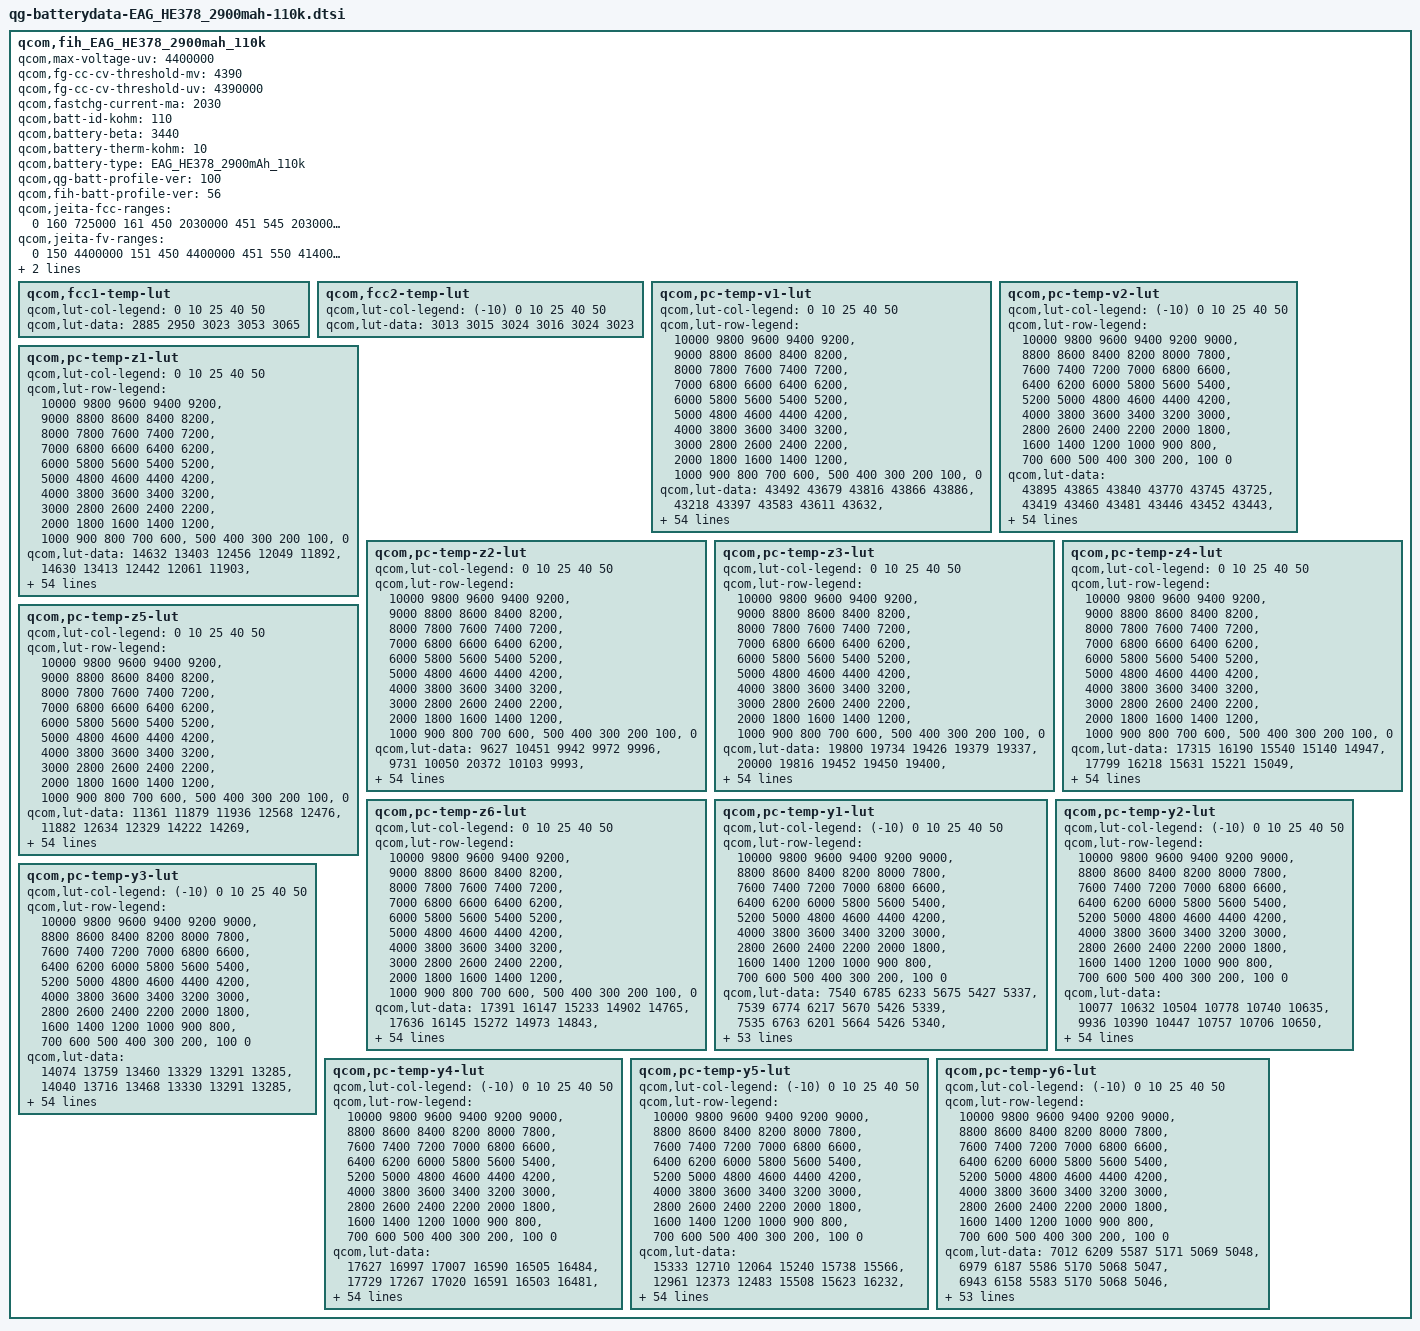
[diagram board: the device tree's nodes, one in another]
qcom,fih_EAG_HE378_2900mah_110k {
	/* 3637030_FIH_Eagles_Scud_3000mAH_averaged_MasterSlave_Nov23rd2018 */
	qcom,max-voltage-uv = <4400000>;
	qcom,fg-cc-cv-threshold-mv = <4390>;
	qcom,fg-cc-cv-threshold-uv = <4390000>;
	qcom,fastchg-current-ma = <2030>;
	qcom,batt-id-kohm = <110>;
	qcom,battery-beta = <3440>;
	qcom,battery-therm-kohm = <10>;
	qcom,battery-type =
		"EAG_HE378_2900mAh_110k";
	qcom,qg-batt-profile-ver = <100>;
	qcom,fih-batt-profile-ver = <56>;

	qcom,jeita-fcc-ranges = <0   160   725000
				 161 450  2030000
				 451 545  2030000
				 546 550  100000>;
	qcom,jeita-fv-ranges =  <0   150  4400000
				 151 450  4400000
				 451 550  4140000>;

	qcom,jeita-soft-thresholds = <0x257d 0xfb3>; 
	qcom,jeita-hard-thresholds = <0x3733 0xc19>;

	qcom,fcc1-temp-lut {
		qcom,lut-col-legend = <0 10 25 40 50>;
		qcom,lut-data = <2885 2950 3023 3053 3065>;
	};

	qcom,fcc2-temp-lut {
		qcom,lut-col-legend = <(-10) 0 10 25 40 50>;
		qcom,lut-data = <3013 3015 3024 3016 3024 3023>;
	};

	qcom,pc-temp-v1-lut {
		qcom,lut-col-legend = <0 10 25 40 50>;
		qcom,lut-row-legend = <10000 9800 9600 9400 9200>,
			<9000 8800 8600 8400 8200>,
			<8000 7800 7600 7400 7200>,
			<7000 6800 6600 6400 6200>,
			<6000 5800 5600 5400 5200>,
			<5000 4800 4600 4400 4200>,
			<4000 3800 3600 3400 3200>,
			<3000 2800 2600 2400 2200>,
			<2000 1800 1600 1400 1200>,
			<1000 900 800 700 600>,
			<500 400 300 200 100>,
			<0>;
		qcom,lut-data = <43492 43679 43816 43866 43886>,
			<43218 43397 43583 43611 43632>,
			<42964 43134 43319 43364 43390>,
			<42722 42890 43058 43122 43150>,
			<42491 42657 42813 42881 42911>,
			<42269 42424 42574 42642 42673>,
			<42052 42194 42339 42406 42437>,
			<41839 41973 42105 42173 42203>,
			<41632 41756 41877 41943 41972>,
			<41435 41546 41653 41714 41744>,
			<41253 41350 41436 41487 41520>,
			<41062 41167 41230 41268 41300>,
			<40845 40972 41036 41058 41081>,
			<40609 40743 40833 40852 40868>,
			<40379 40503 40607 40639 40662>,
			<40143 40281 40382 40427 40462>,
			<39940 40071 40185 40237 40271>,
			<39798 39897 40004 40066 40091>,
			<39687 39773 39844 39903 39918>,
			<39577 39666 39712 39749 39757>,
			<39464 39538 39577 39597 39602>,
			<39352 39390 39393 39405 39419>,
			<39231 39227 39170 39150 39182>,
			<39101 39027 38968 38929 38963>,
			<38973 38812 38770 38782 38808>,
			<38847 38661 38612 38664 38680>,
			<38726 38553 38532 38563 38569>,
			<38623 38472 38478 38476 38470>,
			<38532 38413 38423 38394 38379>,
			<38455 38369 38364 38310 38294>,
			<38394 38327 38306 38233 38216>,
			<38343 38287 38249 38168 38147>,
			<38300 38250 38194 38112 38087>,
			<38266 38216 38144 38061 38030>,
			<38237 38186 38102 38018 37980>,
			<38208 38155 38061 37975 37931>,
			<38182 38127 38022 37927 37875>,
			<38148 38093 37981 37874 37813>,
			<38099 38038 37924 37809 37740>,
			<38032 37950 37835 37723 37653>,
			<37943 37850 37730 37622 37553>,
			<37813 37734 37616 37509 37439>,
			<37682 37599 37485 37377 37308>,
			<37559 37434 37325 37221 37149>,
			<37402 37288 37175 37076 37008>,
			<37285 37182 37082 36986 36921>,
			<37246 37153 37056 36961 36900>,
			<37212 37135 37039 36948 36884>,
			<37183 37110 37019 36930 36866>,
			<37136 37080 36978 36883 36812>,
			<36954 36869 36762 36646 36556>,
			<36515 36443 36336 36217 36123>,
			<35944 35875 35768 35647 35554>,
			<35174 35101 34994 34868 34773>,
			<33948 33886 33789 33665 33569>,
			<30000 30000 30000 30000 30000>;
	};

	qcom,pc-temp-v2-lut {
		qcom,lut-col-legend = <(-10) 0 10 25 40 50>;
		qcom,lut-row-legend = <10000 9800 9600 9400 9200 9000>,
			<8800 8600 8400 8200 8000 7800>,
			<7600 7400 7200 7000 6800 6600>,
			<6400 6200 6000 5800 5600 5400>,
			<5200 5000 4800 4600 4400 4200>,
			<4000 3800 3600 3400 3200 3000>,
			<2800 2600 2400 2200 2000 1800>,
			<1600 1400 1200 1000 900 800>,
			<700 600 500 400 300 200>,
			<100 0>;
		qcom,lut-data = <43895 43865 43840 43770 43745 43725>,
			<43419 43460 43481 43446 43452 43443>,
			<43012 43092 43152 43146 43176 43176>,
			<42694 42764 42857 42874 42917 42922>,
			<42440 42467 42591 42628 42676 42681>,
			<42204 42212 42337 42390 42440 42446>,
			<41967 42011 42090 42156 42206 42212>,
			<41738 41827 41851 41926 41975 41981>,
			<41515 41588 41616 41701 41748 41754>,
			<41283 41284 41380 41479 41524 41529>,
			<41102 41073 41170 41265 41304 41309>,
			<40998 40996 41004 41067 41090 41092>,
			<40896 40932 40841 40872 40880 40880>,
			<40632 40730 40623 40661 40675 40675>,
			<40029 40240 40341 40434 40473 40473>,
			<39581 39847 40086 40222 40278 40281>,
			<39408 39663 39881 40029 40091 40096>,
			<39281 39517 39694 39851 39911 39919>,
			<39135 39345 39514 39699 39745 39751>,
			<38985 39157 39342 39571 39593 39593>,
			<38822 38977 39166 39417 39422 39419>,
			<38616 38815 38974 39183 39204 39204>,
			<38421 38658 38790 38932 38982 38987>,
			<38316 38479 38635 38747 38798 38806>,
			<38248 38280 38499 38596 38635 38645>,
			<38189 38154 38368 38468 38499 38508>,
			<38132 38096 38229 38358 38389 38397>,
			<38079 38053 38106 38260 38292 38298>,
			<38026 38009 38020 38171 38203 38207>,
			<37976 37968 37950 38090 38121 38124>,
			<37925 37929 37900 38016 38048 38049>,
			<37874 37892 37867 37945 37982 37980>,
			<37822 37854 37837 37881 37920 37916>,
			<37769 37816 37806 37828 37856 37854>,
			<37718 37776 37776 37783 37791 37794>,
			<37664 37734 37739 37737 37720 37717>,
			<37605 37690 37696 37687 37639 37608>,
			<37545 37641 37646 37633 37556 37494>,
			<37483 37582 37587 37568 37477 37407>,
			<37419 37513 37520 37493 37398 37329>,
			<37354 37431 37440 37408 37314 37245>,
			<37288 37327 37337 37310 37224 37156>,
			<37217 37213 37214 37194 37116 37047>,
			<37141 37091 37067 37054 36978 36910>,
			<37057 36990 36939 36909 36844 36789>,
			<36951 36908 36852 36850 36802 36754>,
			<36891 36872 36826 36834 36789 36742>,
			<36821 36835 36796 36816 36774 36728>,
			<36731 36793 36760 36788 36747 36700>,
			<36587 36707 36680 36721 36671 36604>,
			<36333 36481 36454 36500 36391 36297>,
			<35934 36047 36015 36047 35917 35811>,
			<35345 35425 35394 35439 35295 35169>,
			<34458 34541 34532 34625 34448 34306>,
			<33189 33247 33193 33394 33197 33040>,
			<28891 28389 28310 28452 28627 28586>;
	};

	qcom,pc-temp-z1-lut {
		qcom,lut-col-legend = <0 10 25 40 50>;
		qcom,lut-row-legend = <10000 9800 9600 9400 9200>,
			<9000 8800 8600 8400 8200>,
			<8000 7800 7600 7400 7200>,
			<7000 6800 6600 6400 6200>,
			<6000 5800 5600 5400 5200>,
			<5000 4800 4600 4400 4200>,
			<4000 3800 3600 3400 3200>,
			<3000 2800 2600 2400 2200>,
			<2000 1800 1600 1400 1200>,
			<1000 900 800 700 600>,
			<500 400 300 200 100>,
			<0>;
		qcom,lut-data = <14632 13403 12456 12049 11892>,
			<14630 13413 12442 12061 11903>,
			<14615 13407 12449 12050 11897>,
			<14599 13392 12450 12040 11893>,
			<14585 13378 12440 12029 11888>,
			<14567 13368 12427 12018 11882>,
			<14556 13361 12416 12010 11877>,
			<14566 13354 12406 12007 11874>,
			<14577 13340 12400 12004 11872>,
			<14565 13326 12395 12000 11869>,
			<14533 13324 12391 11997 11866>,
			<14495 13327 12394 11996 11864>,
			<14446 13328 12405 11996 11863>,
			<14388 13296 12409 11997 11862>,
			<14348 13253 12391 11991 11860>,
			<14319 13246 12371 11978 11858>,
			<14289 13248 12370 11975 11858>,
			<14246 13250 12374 11977 11858>,
			<14197 13252 12378 11980 11858>,
			<14179 13254 12383 11983 11858>,
			<14195 13258 12387 11986 11859>,
			<14214 13267 12391 11988 11860>,
			<14215 13277 12394 11988 11860>,
			<14223 13290 12398 11990 11861>,
			<14234 13305 12408 11992 11862>,
			<14242 13308 12417 11995 11864>,
			<14250 13297 12418 11999 11867>,
			<14256 13288 12418 12004 11872>,
			<14250 13300 12418 12009 11876>,
			<14246 13327 12422 12014 11880>,
			<14265 13335 12426 12018 11884>,
			<14294 13325 12429 12023 11887>,
			<14309 13317 12433 12027 11890>,
			<14310 13322 12438 12031 11893>,
			<14312 13336 12445 12036 11898>,
			<14325 13347 12451 12040 11904>,
			<14357 13358 12456 12045 11907>,
			<14377 13373 12462 12051 11910>,
			<14374 13396 12466 12055 11914>,
			<14368 13428 12475 12059 11918>,
			<14373 13441 12482 12064 11922>,
			<14414 13436 12484 12072 11927>,
			<14426 13428 12486 12080 11931>,
			<14384 13416 12501 12080 11933>,
			<14417 13424 12507 12081 11935>,
			<14444 13446 12509 12087 11939>,
			<14401 13449 12507 12089 11938>,
			<14416 13442 12507 12090 11939>,
			<14454 13475 12505 12090 11941>,
			<14437 13470 12497 12094 11946>,
			<14477 13469 12518 12098 11952>,
			<14453 13510 12531 12108 11962>,
			<14461 13519 12542 12125 11971>,
			<14500 13546 12571 12144 11990>,
			<14500 13546 12571 12144 11990>,
			<14500 13546 12571 12144 11990>;
	};

	qcom,pc-temp-z2-lut {
		qcom,lut-col-legend = <0 10 25 40 50>;
		qcom,lut-row-legend = <10000 9800 9600 9400 9200>,
			<9000 8800 8600 8400 8200>,
			<8000 7800 7600 7400 7200>,
			<7000 6800 6600 6400 6200>,
			<6000 5800 5600 5400 5200>,
			<5000 4800 4600 4400 4200>,
			<4000 3800 3600 3400 3200>,
			<3000 2800 2600 2400 2200>,
			<2000 1800 1600 1400 1200>,
			<1000 900 800 700 600>,
			<500 400 300 200 100>,
			<0>;
		qcom,lut-data = <9627 10451 9942 9972 9996>,
			<9731 10050 20372 10103 9993>,
			<9785 9907 13624 10132 10067>,
			<9820 9900 10066 10145 10111>,
			<9837 9896 10039 10133 10112>,
			<9849 9891 10013 10086 10077>,
			<9852 9886 9995 10057 10049>,
			<9848 9884 9979 10048 10044>,
			<9841 9885 9973 10043 10040>,
			<9834 9884 9981 10043 10013>,
			<9824 9880 9993 10045 9925>,
			<9811 9873 9999 10041 9879>,
			<9795 9869 10003 10002 9893>,
			<9777 9875 10017 9967 9911>,
			<9761 9882 10186 9982 9915>,
			<9745 9880 10366 10016 9915>,
			<9735 9865 10306 10021 9919>,
			<9734 9857 10096 9987 9936>,
			<9737 9870 10012 9958 9957>,
			<9740 9897 10045 9971 9981>,
			<9747 9926 10095 10004 10009>,
			<9755 9960 10149 10055 10024>,
			<9765 9994 10210 10151 10033>,
			<9781 10031 10228 10206 10037>,
			<9798 10065 10205 10133 10040>,
			<9813 10073 10174 10024 10048>,
			<9827 10071 10151 10018 10074>,
			<9836 10066 10129 10082 10174>,
			<9842 10056 10125 10158 10242>,
			<9847 10040 10165 10254 10222>,
			<9853 10036 10207 10335 10175>,
			<9859 10040 10222 10320 10126>,
			<9864 10044 10231 10240 10039>,
			<9869 10046 10233 10204 9998>,
			<9874 10050 10227 10206 10013>,
			<9881 10054 10222 10211 10042>,
			<9890 10057 10224 10233 10088>,
			<9900 10061 10228 10292 10169>,
			<9910 10068 10236 10336 10210>,
			<9920 10079 10266 10368 10214>,
			<9932 10085 10288 10389 10211>,
			<9948 10086 10285 10398 10211>,
			<9890 10088 10282 10400 10212>,
			<9379 10100 10289 10332 10206>,
			<9450 10220 10333 10306 10207>,
			<9480 10279 10362 10290 10219>,
			<9496 10275 10339 10247 10215>,
			<9494 10297 10331 10266 10197>,
			<9506 10293 10335 10316 10235>,
			<9577 10277 10337 10336 10340>,
			<9515 10360 10433 10379 10174>,
			<9422 10165 10400 10229 10025>,
			<9368 9993 10368 10181 9997>,
			<9322 9835 10355 10104 9934>,
			<9322 9835 10355 10104 9934>,
			<9322 9835 10355 10104 9934>;
	};

	qcom,pc-temp-z3-lut {
		qcom,lut-col-legend = <0 10 25 40 50>;
		qcom,lut-row-legend = <10000 9800 9600 9400 9200>,
			<9000 8800 8600 8400 8200>,
			<8000 7800 7600 7400 7200>,
			<7000 6800 6600 6400 6200>,
			<6000 5800 5600 5400 5200>,
			<5000 4800 4600 4400 4200>,
			<4000 3800 3600 3400 3200>,
			<3000 2800 2600 2400 2200>,
			<2000 1800 1600 1400 1200>,
			<1000 900 800 700 600>,
			<500 400 300 200 100>,
			<0>;
		qcom,lut-data = <19800 19734 19426 19379 19337>,
			<20000 19816 19452 19450 19400>,
			<20072 19848 19576 19484 19426>,
			<20104 19858 19637 19502 19443>,
			<20080 19863 19639 19505 19451>,
			<20012 19861 19641 19505 19456>,
			<19970 19854 19639 19504 19458>,
			<19955 19844 19631 19493 19453>,
			<19947 19826 19620 19478 19444>,
			<19946 19806 19600 19470 19434>,
			<19948 19791 19579 19464 19419>,
			<19950 19776 19570 19456 19409>,
			<19964 19766 19563 19443 19405>,
			<19991 19762 19560 19433 19402>,
			<19999 19759 19565 19432 19398>,
			<19975 19751 19570 19431 19394>,
			<19941 19734 19561 19427 19390>,
			<19903 19714 19534 19413 19385>,
			<19860 19687 19513 19401 19379>,
			<19844 19662 19499 19397 19375>,
			<19846 19659 19491 19394 19371>,
			<19850 19668 19500 19397 19371>,
			<19864 19679 19525 19416 19377>,
			<19902 19696 19534 19429 19382>,
			<19931 19717 19529 19412 19371>,
			<19941 19722 19521 19387 19350>,
			<19949 19721 19508 19382 19348>,
			<19950 19719 19490 19382 19366>,
			<19944 19713 19485 19383 19386>,
			<19937 19704 19487 19417 19407>,
			<19929 19697 19492 19460 19425>,
			<19920 19693 19504 19463 19426>,
			<19910 19690 19522 19456 19417>,
			<19899 19686 19527 19447 19406>,
			<19888 19682 19524 19434 19394>,
			<19876 19678 19519 19422 19384>,
			<19865 19674 19514 19417 19382>,
			<19853 19670 19507 19414 19381>,
			<19840 19666 19502 19411 19379>,
			<19826 19661 19496 19406 19375>,
			<19814 19655 19491 19402 19372>,
			<19805 19648 19487 19403 19373>,
			<19739 19639 19483 19404 19377>,
			<19323 19624 19475 19395 19377>,
			<19272 19563 19458 19382 19371>,
			<19271 19537 19435 19372 19360>,
			<19270 19530 19433 19371 19350>,
			<19270 19502 19426 19361 19349>,
			<19270 19494 19428 19360 19343>,
			<19267 19354 19420 19348 19336>,
			<19269 19482 19395 19353 19364>,
			<19272 19384 19411 19364 19375>,
			<19275 19320 19402 19370 19373>,
			<19277 19307 19352 19372 19375>,
			<19277 19307 19352 19372 19375>,
			<19277 19307 19352 19372 19375>;
	};

	qcom,pc-temp-z4-lut {
		qcom,lut-col-legend = <0 10 25 40 50>;
		qcom,lut-row-legend = <10000 9800 9600 9400 9200>,
			<9000 8800 8600 8400 8200>,
			<8000 7800 7600 7400 7200>,
			<7000 6800 6600 6400 6200>,
			<6000 5800 5600 5400 5200>,
			<5000 4800 4600 4400 4200>,
			<4000 3800 3600 3400 3200>,
			<3000 2800 2600 2400 2200>,
			<2000 1800 1600 1400 1200>,
			<1000 900 800 700 600>,
			<500 400 300 200 100>,
			<0>;
		qcom,lut-data = <17315 16190 15540 15140 14947>,
			<17799 16218 15631 15221 15049>,
			<17425 16177 15471 15157 15033>,
			<16950 15930 15312 15054 14970>,
			<16645 15618 15192 14987 14921>,
			<16393 15438 15087 14933 14879>,
			<16181 15303 15009 14890 14845>,
			<16000 15201 14946 14854 14817>,
			<15846 15123 14901 14827 14795>,
			<15715 15060 14871 14809 14787>,
			<15603 15007 14847 14796 14784>,
			<15505 14961 14827 14787 14779>,
			<15411 14928 14810 14781 14768>,
			<15331 14905 14798 14775 14754>,
			<15288 14890 14781 14766 14742>,
			<15266 14883 14767 14756 14731>,
			<15245 14879 14766 14744 14721>,
			<15209 14873 14763 14731 14711>,
			<15158 14855 14759 14720 14702>,
			<15109 14833 14751 14714 14696>,
			<15062 14824 14745 14709 14691>,
			<15017 14820 14762 14720 14697>,
			<14974 14819 14816 14800 14772>,
			<14929 14860 14866 14872 14848>,
			<14908 14938 14941 14908 14882>,
			<14912 14968 14999 14936 14908>,
			<14923 14977 14996 14936 14907>,
			<14933 14981 14976 14918 14871>,
			<14946 14973 14954 14892 14827>,
			<14954 14952 14928 14837 14785>,
			<14954 14933 14900 14778 14746>,
			<14949 14916 14869 14758 14731>,
			<14944 14900 14837 14748 14722>,
			<14937 14887 14821 14744 14719>,
			<14929 14875 14812 14742 14718>,
			<14919 14864 14808 14741 14718>,
			<14908 14853 14808 14743 14721>,
			<14896 14845 14808 14750 14730>,
			<14884 14844 14809 14758 14739>,
			<14873 14845 14823 14772 14752>,
			<14863 14845 14834 14783 14761>,
			<14854 14835 14824 14775 14754>,
			<14900 14821 14805 14761 14741>,
			<15296 14807 14796 14768 14745>,
			<15195 14769 14767 14760 14742>,
			<15154 14743 14735 14729 14717>,
			<15145 14740 14723 14717 14710>,
			<15136 14753 14707 14699 14687>,
			<15130 14751 14686 14674 14663>,
			<15116 14896 14689 14683 14666>,
			<15110 14757 14740 14718 14682>,
			<15134 14884 14732 14714 14678>,
			<15143 14958 14741 14706 14680>,
			<15160 14979 14795 14703 14676>,
			<15160 14979 14795 14703 14676>,
			<15160 14979 14795 14703 14676>;
	};

	qcom,pc-temp-z5-lut {
		qcom,lut-col-legend = <0 10 25 40 50>;
		qcom,lut-row-legend = <10000 9800 9600 9400 9200>,
			<9000 8800 8600 8400 8200>,
			<8000 7800 7600 7400 7200>,
			<7000 6800 6600 6400 6200>,
			<6000 5800 5600 5400 5200>,
			<5000 4800 4600 4400 4200>,
			<4000 3800 3600 3400 3200>,
			<3000 2800 2600 2400 2200>,
			<2000 1800 1600 1400 1200>,
			<1000 900 800 700 600>,
			<500 400 300 200 100>,
			<0>;
		qcom,lut-data = <11361 11879 11936 12568 12476>,
			<11882 12634 12329 14222 14269>,
			<12301 13197 13727 15119 14962>,
			<12587 13589 14808 15769 15736>,
			<12709 13950 15369 16214 16379>,
			<12783 14400 15832 16540 16937>,
			<12882 14904 16408 16805 17360>,
			<13061 15351 17081 17016 17788>,
			<13280 15703 17556 17213 18171>,
			<13476 16045 17793 17495 18040>,
			<13665 16428 18012 17827 17238>,
			<13901 16849 18399 17900 16822>,
			<14588 17461 19011 17522 17153>,
			<15598 19464 19808 17192 17710>,
			<15861 21745 21572 17674 18186>,
			<15309 21658 23126 18771 18672>,
			<14703 19629 22668 19077 19097>,
			<14497 18351 21008 18708 19572>,
			<14379 18364 20371 18401 20154>,
			<14419 18494 21202 18746 20871>,
			<14877 19319 22852 19750 21753>,
			<15763 23153 27354 22036 22713>,
			<17347 27645 35643 28579 24250>,
			<20617 32576 38348 32611 25221>,
			<23944 37640 34323 27500 22136>,
			<27051 38593 28997 19257 16397>,
			<29768 36042 24953 16560 15045>,
			<30480 32904 21004 15457 15176>,
			<30469 30440 19513 15117 15491>,
			<30346 28186 19138 17867 17390>,
			<29959 27216 18974 22098 20342>,
			<29101 26825 20166 24472 22087>,
			<28189 26637 23195 26273 23400>,
			<27170 26735 25336 26864 24047>,
			<26158 27023 26924 26662 24247>,
			<25441 27207 27786 26359 24344>,
			<24837 27285 27699 26165 24330>,
			<24456 27363 27387 26009 24229>,
			<24094 27554 26847 25553 23925>,
			<23684 27895 25276 22916 21456>,
			<23671 28020 23880 20462 18956>,
			<24103 27165 23458 20295 18784>,
			<22934 26213 23119 20332 18930>,
			<11921 25773 22220 18527 18475>,
			<11130 24603 22907 17947 17888>,
			<11149 24440 22428 18104 17509>,
			<11105 22992 22532 18356 16598>,
			<11097 18764 21856 18064 17662>,
			<11075 18543 23987 20190 19819>,
			<11061 12306 22528 18009 18250>,
			<11106 17779 16447 15088 17657>,
			<11114 12736 16489 15032 17960>,
			<11052 11717 15212 15201 17000>,
			<10945 11335 12657 15013 16816>,
			<10945 11335 12657 15013 16816>,
			<10945 11335 12657 15013 16816>;
	};

	qcom,pc-temp-z6-lut {
		qcom,lut-col-legend = <0 10 25 40 50>;
		qcom,lut-row-legend = <10000 9800 9600 9400 9200>,
			<9000 8800 8600 8400 8200>,
			<8000 7800 7600 7400 7200>,
			<7000 6800 6600 6400 6200>,
			<6000 5800 5600 5400 5200>,
			<5000 4800 4600 4400 4200>,
			<4000 3800 3600 3400 3200>,
			<3000 2800 2600 2400 2200>,
			<2000 1800 1600 1400 1200>,
			<1000 900 800 700 600>,
			<500 400 300 200 100>,
			<0>;
		qcom,lut-data = <17391 16147 15233 14902 14765>,
			<17636 16145 15272 14973 14843>,
			<17453 16122 15251 14954 14844>,
			<17203 15991 15222 14923 14829>,
			<17004 15826 15172 14899 14814>,
			<16816 15724 15112 14874 14799>,
			<16663 15644 15069 14851 14784>,
			<16542 15576 15034 14828 14769>,
			<16442 15515 15004 14808 14755>,
			<16364 15464 14977 14795 14743>,
			<16300 15424 14956 14785 14734>,
			<16241 15389 14941 14776 14725>,
			<16181 15361 14930 14767 14717>,
			<16124 15337 14922 14758 14709>,
			<16074 15317 14916 14751 14702>,
			<16027 15303 14910 14745 14694>,
			<15981 15290 14900 14737 14687>,
			<15930 15277 14885 14723 14679>,
			<15877 15257 14872 14712 14672>,
			<15843 15239 14863 14707 14667>,
			<15823 15236 14858 14704 14662>,
			<15811 15241 14870 14710 14665>,
			<15812 15249 14907 14757 14702>,
			<15818 15277 14936 14792 14736>,
			<15827 15321 14966 14798 14743>,
			<15839 15339 14987 14799 14746>,
			<15852 15346 14982 14796 14744>,
			<15860 15348 14966 14789 14739>,
			<15865 15344 14953 14782 14733>,
			<15868 15334 14944 14778 14727>,
			<15866 15325 14937 14775 14721>,
			<15860 15317 14932 14770 14714>,
			<15855 15311 14929 14763 14707>,
			<15853 15305 14925 14756 14700>,
			<15851 15300 14922 14748 14693>,
			<15848 15297 14919 14742 14688>,
			<15842 15297 14918 14742 14688>,
			<15837 15296 14917 14743 14691>,
			<15834 15298 14917 14745 14694>,
			<15830 15304 14922 14750 14698>,
			<15829 15307 14926 14753 14700>,
			<15829 15305 14923 14751 14699>,
			<15826 15303 14916 14747 14695>,
			<15807 15298 14911 14745 14697>,
			<15757 15262 14895 14737 14694>,
			<15740 15246 14873 14719 14678>,
			<15739 15243 14867 14713 14670>,
			<15737 15234 14857 14701 14659>,
			<15738 15232 14850 14689 14645>,
			<15742 15229 14851 14688 14643>,
			<15755 15246 14864 14707 14667>,
			<15780 15263 14875 14715 14674>,
			<15806 15281 14882 14718 14677>,
			<15848 15307 14891 14723 14680>,
			<15848 15307 14891 14723 14680>,
			<15848 15307 14891 14723 14680>;
	};

	qcom,pc-temp-y1-lut {
		qcom,lut-col-legend = <(-10) 0 10 25 40 50>;
		qcom,lut-row-legend = <10000 9800 9600 9400 9200 9000>,
			<8800 8600 8400 8200 8000 7800>,
			<7600 7400 7200 7000 6800 6600>,
			<6400 6200 6000 5800 5600 5400>,
			<5200 5000 4800 4600 4400 4200>,
			<4000 3800 3600 3400 3200 3000>,
			<2800 2600 2400 2200 2000 1800>,
			<1600 1400 1200 1000 900 800>,
			<700 600 500 400 300 200>,
			<100 0>;
		qcom,lut-data = <7540 6785 6233 5675 5427 5337>,
			<7539 6774 6217 5670 5426 5339>,
			<7535 6763 6201 5664 5426 5340>,
			<7529 6752 6187 5658 5425 5339>,
			<7524 6744 6177 5653 5424 5338>,
			<7521 6739 6172 5651 5424 5336>,
			<7519 6735 6173 5650 5422 5333>,
			<7516 6734 6175 5649 5420 5330>,
			<7518 6740 6176 5649 5417 5328>,
			<7530 6765 6176 5648 5413 5328>,
			<7537 6780 6178 5646 5410 5327>,
			<7527 6777 6182 5643 5408 5325>,
			<7513 6771 6186 5639 5407 5323>,
			<7517 6773 6185 5638 5405 5321>,
			<7544 6786 6183 5640 5402 5320>,
			<7559 6794 6181 5642 5401 5320>,
			<7550 6781 6183 5648 5402 5320>,
			<7539 6764 6187 5655 5404 5320>,
			<7534 6761 6188 5655 5404 5320>,
			<7522 6759 6189 5651 5402 5319>,
			<7516 6759 6189 5648 5401 5319>,
			<7540 6766 6186 5647 5403 5320>,
			<7571 6775 6183 5648 5405 5321>,
			<7575 6775 6186 5650 5406 5322>,
			<7574 6772 6192 5656 5407 5323>,
			<7572 6772 6195 5662 5408 5325>,
			<7553 6790 6195 5666 5411 5327>,
			<7531 6811 6195 5670 5414 5330>,
			<7527 6811 6193 5673 5418 5332>,
			<7528 6798 6187 5676 5421 5334>,
			<7529 6792 6185 5678 5424 5336>,
			<7529 6791 6194 5679 5429 5339>,
			<7529 6788 6203 5680 5433 5342>,
			<7529 6785 6204 5683 5438 5345>,
			<7530 6782 6205 5691 5443 5349>,
			<7530 6777 6203 5696 5447 5352>,
			<7536 6767 6199 5700 5450 5354>,
			<7548 6758 6197 5703 5452 5356>,
			<7570 6762 6200 5705 5454 5358>,
			<7612 6774 6206 5707 5457 5361>,
			<7626 6779 6208 5710 5460 5364>,
			<7576 6774 6206 5721 5466 5366>,
			<7547 6772 6205 5727 5469 5369>,
			<7562 6785 6214 5730 5470 5372>,
			<7588 6781 6215 5737 5479 5376>,
			<7620 6844 6231 5742 5481 5381>,
			<7642 6838 6226 5745 5487 5382>,
			<7633 6852 6220 5749 5488 5383>,
			<7633 6838 6238 5753 5491 5383>,
			<7651 6847 6236 5752 5487 5382>,
			<7638 6858 6257 5750 5492 5384>,
			<7660 6889 6257 5761 5501 5392>,
			<7768 6897 6302 5774 5512 5401>,
			<7883 6903 6319 5781 5528 5415>,
			<7883 6903 6319 5781 5528 5415>,
			<7883 6903 6319 5781 5528 5415>;
	};

	qcom,pc-temp-y2-lut {
		qcom,lut-col-legend = <(-10) 0 10 25 40 50>;
		qcom,lut-row-legend = <10000 9800 9600 9400 9200 9000>,
			<8800 8600 8400 8200 8000 7800>,
			<7600 7400 7200 7000 6800 6600>,
			<6400 6200 6000 5800 5600 5400>,
			<5200 5000 4800 4600 4400 4200>,
			<4000 3800 3600 3400 3200 3000>,
			<2800 2600 2400 2200 2000 1800>,
			<1600 1400 1200 1000 900 800>,
			<700 600 500 400 300 200>,
			<100 0>;
		qcom,lut-data = <10077 10632 10504 10778 10740 10635>,
			<9936 10390 10447 10757 10706 10650>,
			<9879 10203 10413 10734 10675 10653>,
			<9884 10071 10396 10711 10649 10647>,
			<9933 9993 10389 10690 10631 10635>,
			<10005 9968 10389 10674 10621 10619>,
			<10159 10012 10415 10660 10623 10589>,
			<10328 10098 10453 10647 10628 10558>,
			<10275 10227 10431 10637 10623 10552>,
			<9897 10532 10313 10629 10600 10556>,
			<9672 10710 10249 10618 10588 10560>,
			<9678 10563 10421 10594 10627 10559>,
			<9687 10352 10648 10570 10679 10557>,
			<9686 10355 10661 10592 10685 10557>,
			<9673 10448 10597 10703 10683 10558>,
			<9665 10541 10565 10781 10683 10564>,
			<9664 10632 10607 10799 10742 10633>,
			<9664 10705 10670 10813 10837 10736>,
			<9663 10713 10705 10861 10909 10809>,
			<9663 10693 10730 10969 10976 10873>,
			<9662 10649 10752 11021 11003 10904>,
			<9662 10273 10768 10965 10982 10886>,
			<9661 9809 10784 10896 10952 10858>,
			<9661 9715 10816 10897 10927 10847>,
			<9660 9688 10863 10934 10889 10824>,
			<9659 9677 10878 10964 10876 10815>,
			<9659 9673 10819 10981 10894 10842>,
			<9658 9670 10753 10998 10929 10886>,
			<9658 9667 10743 11032 10982 10929>,
			<9658 9665 10745 11089 11063 10978>,
			<9658 9663 10738 11115 11129 11019>,
			<9657 9661 10704 11117 11184 11049>,
			<9657 9660 10662 11116 11221 11081>,
			<9657 9659 10633 11105 11225 11147>,
			<9657 9658 10607 11073 11219 11247>,
			<9657 9657 10530 11035 11208 11273>,
			<9657 9657 10108 10993 11188 11176>,
			<9657 9656 9728 10945 11168 11067>,
			<9657 9656 9692 10895 11137 11025>,
			<9657 9656 9679 10840 11088 10996>,
			<9656 9656 9672 10789 11071 10973>,
			<9656 9656 9667 10746 11080 10946>,
			<9656 9655 9664 10702 11079 10943>,
			<9656 9655 9661 10652 11059 10976>,
			<9656 9655 9659 10568 10874 10847>,
			<9656 9655 9659 10554 10820 10745>,
			<9655 9655 9658 10538 10829 10734>,
			<9655 9655 9657 10528 10842 10792>,
			<9655 9655 9656 10510 10839 10797>,
			<9655 9654 9656 10483 10842 10794>,
			<9655 9654 9655 10438 10811 10712>,
			<9654 9654 9655 10378 10734 10629>,
			<9652 9654 9654 10323 10666 10532>,
			<9650 9653 9654 10278 10592 10488>,
			<9650 9653 9654 10278 10592 10488>,
			<9650 9653 9654 10278 10592 10488>;
	};

	qcom,pc-temp-y3-lut {
		qcom,lut-col-legend = <(-10) 0 10 25 40 50>;
		qcom,lut-row-legend = <10000 9800 9600 9400 9200 9000>,
			<8800 8600 8400 8200 8000 7800>,
			<7600 7400 7200 7000 6800 6600>,
			<6400 6200 6000 5800 5600 5400>,
			<5200 5000 4800 4600 4400 4200>,
			<4000 3800 3600 3400 3200 3000>,
			<2800 2600 2400 2200 2000 1800>,
			<1600 1400 1200 1000 900 800>,
			<700 600 500 400 300 200>,
			<100 0>;
		qcom,lut-data = <14074 13759 13460 13329 13291 13285>,
			<14040 13716 13468 13330 13291 13285>,
			<14015 13690 13473 13331 13292 13285>,
			<14000 13677 13477 13333 13293 13286>,
			<13991 13672 13478 13335 13294 13287>,
			<13990 13672 13478 13336 13295 13288>,
			<14008 13723 13474 13338 13296 13289>,
			<14034 13799 13469 13340 13297 13291>,
			<13990 13774 13477 13342 13298 13292>,
			<13763 13598 13514 13344 13298 13293>,
			<13629 13491 13534 13345 13299 13294>,
			<13682 13513 13497 13347 13303 13295>,
			<13757 13547 13446 13348 13308 13296>,
			<13755 13554 13434 13348 13308 13296>,
			<13693 13558 13430 13350 13308 13296>,
			<13656 13557 13428 13351 13308 13296>,
			<13658 13530 13426 13344 13308 13298>,
			<13665 13491 13424 13335 13308 13301>,
			<13676 13460 13419 13335 13308 13301>,
			<13702 13429 13410 13340 13307 13300>,
			<13714 13417 13400 13342 13306 13299>,
			<13686 13431 13391 13334 13303 13295>,
			<13649 13449 13381 13324 13299 13290>,
			<13651 13439 13372 13318 13295 13288>,
			<13684 13397 13364 13315 13291 13286>,
			<13724 13376 13357 13313 13289 13285>,
			<13771 13389 13354 13312 13288 13284>,
			<13823 13414 13351 13311 13288 13284>,
			<13872 13445 13346 13310 13288 13284>,
			<13921 13491 13339 13310 13288 13283>,
			<13968 13539 13338 13309 13288 13283>,
			<14010 13589 13345 13308 13290 13283>,
			<14051 13641 13354 13308 13291 13284>,
			<14095 13693 13359 13308 13291 13284>,
			<14141 13745 13364 13310 13290 13286>,
			<14182 13800 13371 13311 13289 13286>,
			<14216 13857 13382 13313 13288 13283>,
			<14250 13915 13396 13315 13288 13280>,
			<14292 13971 13412 13316 13288 13280>,
			<14340 14027 13431 13317 13287 13281>,
			<14392 14080 13454 13318 13287 13282>,
			<14446 14129 13485 13321 13290 13283>,
			<14506 14181 13528 13324 13292 13284>,
			<14575 14240 13594 13327 13292 13282>,
			<14652 14308 13684 13329 13289 13282>,
			<14598 14279 13686 13328 13293 13288>,
			<14690 14355 13771 13334 13296 13291>,
			<14771 14426 13858 13341 13303 13297>,
			<14869 14504 13958 13349 13310 13301>,
			<14975 14573 14060 13360 13312 13299>,
			<15080 14635 14151 13362 13307 13294>,
			<15296 14718 14262 13366 13308 13295>,
			<15887 14832 14404 13381 13315 13297>,
			<16943 15120 14528 13401 13324 13306>,
			<16943 15120 14528 13401 13324 13306>,
			<16943 15120 14528 13401 13324 13306>;
	};

	qcom,pc-temp-y4-lut {
		qcom,lut-col-legend = <(-10) 0 10 25 40 50>;
		qcom,lut-row-legend = <10000 9800 9600 9400 9200 9000>,
			<8800 8600 8400 8200 8000 7800>,
			<7600 7400 7200 7000 6800 6600>,
			<6400 6200 6000 5800 5600 5400>,
			<5200 5000 4800 4600 4400 4200>,
			<4000 3800 3600 3400 3200 3000>,
			<2800 2600 2400 2200 2000 1800>,
			<1600 1400 1200 1000 900 800>,
			<700 600 500 400 300 200>,
			<100 0>;
		qcom,lut-data = <17627 16997 17007 16590 16505 16484>,
			<17729 17267 17020 16591 16503 16481>,
			<17774 17430 17027 16593 16500 16477>,
			<17774 17513 17030 16594 16498 16474>,
			<17741 17544 17029 16594 16497 16472>,
			<17688 17547 17027 16595 16497 16471>,
			<17514 17456 17019 16594 16499 16472>,
			<17303 17322 17003 16593 16501 16473>,
			<17399 17352 16971 16594 16504 16475>,
			<18009 17604 16903 16600 16512 16478>,
			<18372 17787 16870 16607 16517 16482>,
			<18301 17874 17026 16616 16519 16488>,
			<18148 17939 17231 16627 16521 16496>,
			<17918 17813 17231 16644 16528 16504>,
			<17503 17342 17123 16675 16549 16515>,
			<17277 17085 17047 16702 16568 16525>,
			<17261 17121 17003 16721 16581 16533>,
			<17250 17167 16964 16738 16594 16542>,
			<17211 17165 16946 16756 16617 16560>,
			<17116 17123 16926 16775 16652 16591>,
			<17033 17070 16899 16781 16665 16604>,
			<16971 17001 16845 16710 16622 16577>,
			<16927 16924 16787 16612 16562 16539>,
			<16923 16858 16757 16575 16527 16511>,
			<16927 16795 16736 16553 16498 16482>,
			<16929 16770 16707 16547 16488 16471>,
			<16929 16780 16638 16549 16493 16475>,
			<16929 16791 16577 16553 16501 16481>,
			<16927 16792 16565 16560 16510 16490>,
			<16925 16792 16562 16569 16524 16503>,
			<16924 16791 16566 16573 16537 16517>,
			<16930 16795 16576 16570 16554 16533>,
			<16936 16801 16589 16568 16566 16547>,
			<16938 16809 16605 16568 16566 16556>,
			<16938 16820 16626 16571 16566 16561>,
			<16940 16831 16656 16573 16563 16561>,
			<16944 16842 16707 16573 16538 16527>,
			<16950 16852 16753 16573 16513 16495>,
			<16957 16858 16776 16574 16509 16493>,
			<16967 16862 16792 16576 16507 16492>,
			<16979 16863 16797 16579 16507 16493>,
			<17000 16845 16798 16586 16512 16498>,
			<17023 16824 16796 16594 16514 16499>,
			<17050 16806 16778 16601 16508 16490>,
			<17054 16802 16757 16590 16490 16469>,
			<16969 16785 16744 16572 16493 16474>,
			<16986 16804 16760 16591 16509 16489>,
			<17008 16836 16786 16615 16523 16511>,
			<17029 16871 16823 16648 16551 16549>,
			<17034 16905 16873 16676 16574 16553>,
			<17019 16899 16878 16661 16517 16492>,
			<17034 16862 16856 16650 16511 16483>,
			<17190 16855 16854 16672 16529 16491>,
			<17585 16924 16863 16714 16575 16534>,
			<17585 16924 16863 16714 16575 16534>,
			<17585 16924 16863 16714 16575 16534>;
	};

	qcom,pc-temp-y5-lut {
		qcom,lut-col-legend = <(-10) 0 10 25 40 50>;
		qcom,lut-row-legend = <10000 9800 9600 9400 9200 9000>,
			<8800 8600 8400 8200 8000 7800>,
			<7600 7400 7200 7000 6800 6600>,
			<6400 6200 6000 5800 5600 5400>,
			<5200 5000 4800 4600 4400 4200>,
			<4000 3800 3600 3400 3200 3000>,
			<2800 2600 2400 2200 2000 1800>,
			<1600 1400 1200 1000 900 800>,
			<700 600 500 400 300 200>,
			<100 0>;
		qcom,lut-data = <15333 12710 12064 15240 15738 15566>,
			<12961 12373 12483 15508 15623 16232>,
			<11981 12182 12953 15718 15470 16625>,
			<12057 12106 13414 15868 15297 16811>,
			<12853 12117 13806 15960 15118 16855>,
			<14040 12190 14069 15994 14948 16822>,
			<16765 14039 14206 15963 14768 16622>,
			<19800 16673 14328 15882 14562 16293>,
			<19246 16381 14763 15734 14269 16015>,
			<14338 13016 15970 15369 13767 15732>,
			<11433 11050 16547 14916 13524 15405>,
			<14094 12931 14929 14229 13899 14995>,
			<17843 15813 12863 13589 14392 14536>,
			<17639 17000 13265 13603 14259 14042>,
			<14195 17783 15798 14027 13488 13481>,
			<12249 18089 17085 14259 13040 13251>,
			<12780 17341 16871 14110 12984 13365>,
			<13762 16351 16611 13917 12983 13526>,
			<14820 16252 16754 14567 13107 13556>,
			<16294 16419 17368 17206 13543 13490>,
			<16948 16698 17783 18699 14221 13589>,
			<14757 18127 17949 18734 16496 15145>,
			<11888 19755 18090 18598 18744 17017>,
			<11404 18642 18282 18297 18513 17580>,
			<11328 13872 18591 17728 17075 17872>,
			<11307 11420 18932 17362 15995 17914>,
			<11344 11329 19993 17172 15364 16882>,
			<11413 11287 20934 17044 14945 15576>,
			<11505 11326 19538 17081 14794 14958>,
			<11652 11499 15750 17289 14746 14450>,
			<11748 11682 14344 17597 14872 14271>,
			<11772 11883 14821 18406 15536 14300>,
			<11788 12065 15318 19228 16236 14402>,
			<11861 12171 15457 19386 16484 15006>,
			<11996 12294 15572 19323 16680 16294>,
			<12053 12420 15390 19183 16940 16728>,
			<12026 12603 14100 18731 17389 16465>,
			<11989 12792 12961 18067 17709 16110>,
			<11973 12917 12898 17255 17207 15824>,
			<11967 13020 12894 16139 16021 15542>,
			<11970 13056 12864 15458 15611 15395>,
			<11976 12991 12756 15121 15875 15365>,
			<11992 12863 12645 14830 16113 15422>,
			<12102 12514 12543 14499 16299 15710>,
			<12302 12320 12766 14744 15860 15760>,
			<12411 12335 12440 14914 15277 15835>,
			<12497 12247 12613 14691 14732 15155>,
			<12603 12219 12559 14292 15127 15633>,
			<12819 12519 12697 13953 15360 15422>,
			<13043 12826 12752 13992 15437 14653>,
			<13034 12774 12783 14437 16681 16069>,
			<12701 12554 12689 15018 17513 16577>,
			<11785 12492 12662 15586 18792 16697>,
			<10886 12227 12840 16615 20383 21010>,
			<10886 12227 12840 16615 20383 21010>,
			<10886 12227 12840 16615 20383 21010>;
	};

	qcom,pc-temp-y6-lut {
		qcom,lut-col-legend = <(-10) 0 10 25 40 50>;
		qcom,lut-row-legend = <10000 9800 9600 9400 9200 9000>,
			<8800 8600 8400 8200 8000 7800>,
			<7600 7400 7200 7000 6800 6600>,
			<6400 6200 6000 5800 5600 5400>,
			<5200 5000 4800 4600 4400 4200>,
			<4000 3800 3600 3400 3200 3000>,
			<2800 2600 2400 2200 2000 1800>,
			<1600 1400 1200 1000 900 800>,
			<700 600 500 400 300 200>,
			<100 0>;
		qcom,lut-data = <7012 6209 5587 5171 5069 5048>,
			<6979 6187 5586 5170 5068 5047>,
			<6943 6158 5583 5170 5068 5046>,
			<6905 6128 5577 5169 5068 5046>,
			<6866 6105 5571 5169 5069 5046>,
			<6826 6096 5563 5168 5069 5047>,
			<6779 6099 5551 5169 5070 5047>,
			<6735 6104 5539 5169 5071 5048>,
			<6709 6096 5534 5170 5073 5050>,
			<6686 6058 5530 5171 5074 5052>,
			<6675 6035 5530 5173 5077 5054>,
			<6683 6070 5545 5176 5079 5056>,
			<6694 6118 5563 5179 5083 5058>,
			<6655 6098 5557 5184 5087 5061>,
			<6496 5983 5525 5195 5091 5064>,
			<6407 5913 5501 5201 5096 5067>,
			<6410 5907 5489 5201 5100 5070>,
			<6414 5904 5477 5201 5104 5075>,
			<6413 5894 5468 5205 5110 5080>,
			<6408 5874 5456 5213 5118 5088>,
			<6402 5857 5443 5217 5121 5091>,
			<6378 5847 5423 5192 5107 5080>,
			<6351 5838 5404 5156 5086 5065>,
			<6355 5824 5394 5143 5073 5054>,
			<6386 5805 5387 5135 5062 5045>,
			<6423 5798 5378 5132 5058 5041>,
			<6460 5827 5362 5133 5059 5042>,
			<6499 5876 5350 5135 5061 5044>,
			<6537 5921 5352 5137 5064 5046>,
			<6575 5970 5360 5141 5069 5050>,
			<6611 6020 5373 5143 5073 5054>,
			<6645 6071 5399 5144 5080 5059>,
			<6678 6122 5434 5145 5084 5063>,
			<6711 6171 5468 5147 5085 5067>,
			<6744 6219 5506 5151 5084 5070>,
			<6776 6267 5545 5156 5083 5069>,
			<6806 6316 5584 5161 5076 5058>,
			<6837 6365 5626 5166 5070 5047>,
			<6872 6414 5671 5172 5069 5047>,
			<6912 6461 5719 5178 5068 5048>,
			<6956 6503 5771 5186 5069 5049>,
			<7003 6537 5827 5197 5074 5052>,
			<7055 6575 5888 5210 5076 5052>,
			<7116 6620 5957 5225 5075 5049>,
			<7192 6674 6040 5235 5070 5044>,
			<7146 6656 6041 5226 5074 5051>,
			<7227 6717 6120 5245 5082 5057>,
			<7301 6784 6200 5266 5091 5068>,
			<7383 6856 6294 5294 5104 5082>,
			<7472 6922 6394 5325 5113 5082>,
			<7557 6972 6474 5337 5093 5061>,
			<7751 7033 6560 5363 5094 5059>,
			<8332 7128 6680 5426 5108 5065>,
			<9336 7397 6794 5502 5131 5086>,
			<9336 7397 6794 5502 5131 5086>,
			<9336 7397 6794 5502 5131 5086>;
	};

};
